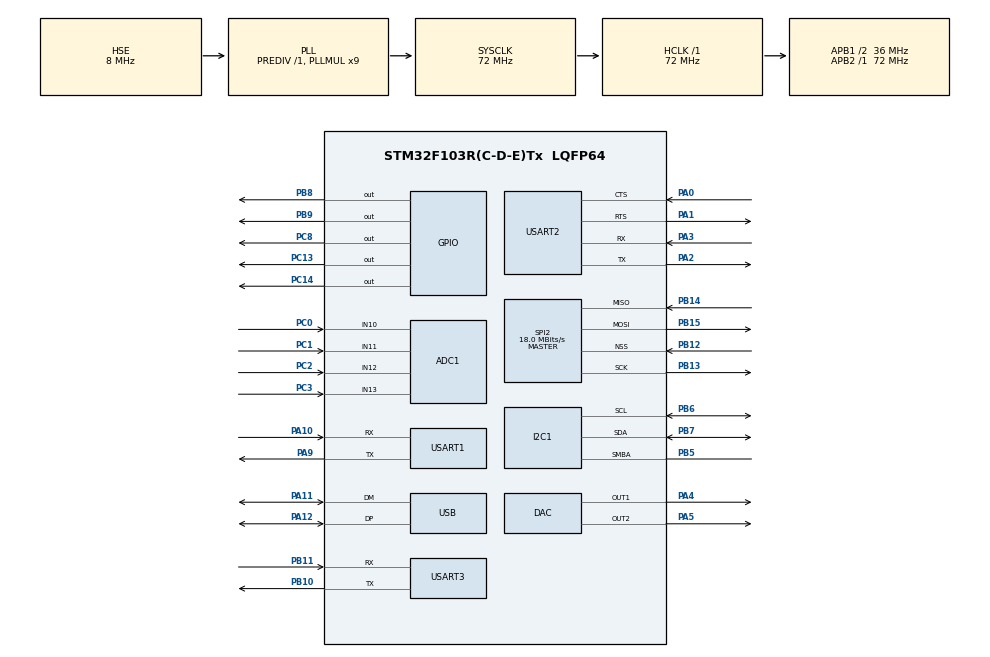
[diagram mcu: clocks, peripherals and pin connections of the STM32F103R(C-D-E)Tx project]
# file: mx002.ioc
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ADC1.Channel-0\#ChannelRegularConversion=ADC_CHANNEL_10
ADC1.ContinuousConvMode=DISABLE
ADC1.DataAlign=ADC_DATAALIGN_RIGHT
ADC1.DiscontinuousConvMode=DISABLE
ADC1.EnableAnalogWatchDog=false
ADC1.EnableRegularConversion=ENABLE
ADC1.ExternalTrigConv=ADC_SOFTWARE_START
ADC1.InjNumberOfConversion=0
ADC1.NbrOfConversion=1
ADC1.NbrOfConversionFlag=1
ADC1.Rank-0\#ChannelRegularConversion=1
ADC1.SamplingTime-0\#ChannelRegularConversion=ADC_SAMPLETIME_1CYCLE_5
ADC1.ScanConvMode=ADC_SCAN_DISABLE
ADC1.master=1
Mcu.Family=STM32F1
Mcu.Name=STM32F103R(C-D-E)Tx
Mcu.Package=LQFP64
NVIC.PriorityGroup=NVIC_PRIORITYGROUP_4
PA0-WKUP.Mode=CTS_RTS
PA0-WKUP.Signal=USART2_CTS
PA1.Mode=CTS_RTS
PA1.Signal=USART2_RTS
PA10.Mode=Asynchronous
PA10.Signal=USART1_RX
PA11.Mode=Device
PA11.Signal=USB_DM
PA12.Mode=Device
PA12.Signal=USB_DP
PA13.Mode=JTAG_5_pins
PA13.Signal=SYS_JTMS-SWDIO
PA14.Mode=JTAG_5_pins
PA14.Signal=SYS_JTCK-SWCLK
PA15.Mode=JTAG_5_pins
PA15.Signal=SYS_JTDI
PA2.Mode=Asynchronous
PA2.Signal=USART2_TX
PA3.Mode=Asynchronous
PA3.Signal=USART2_RX
PA4.Signal=COMP_DAC1_group
PA5.Signal=COMP_DAC2_group
PA9.Mode=Asynchronous
PA9.Signal=USART1_TX
PB10.Mode=Asynchronous
PB10.Signal=USART3_TX
PB11.Mode=Asynchronous
PB11.Signal=USART3_RX
PB12.Mode=NSS_Signal_Hard_Input
PB12.Signal=SPI2_NSS
PB13.Mode=Full_Duplex_Master
PB13.Signal=SPI2_SCK
PB14.Mode=Full_Duplex_Master
PB14.Signal=SPI2_MISO
PB15.Mode=Full_Duplex_Master
PB15.Signal=SPI2_MOSI
PB3.Mode=JTAG_5_pins
PB3.Signal=SYS_JTDO-TRACESWO
PB4.Mode=JTAG_5_pins
PB4.Signal=SYS_NJTRST
PB5.Mode=SMBus-Alert-mode
PB5.Signal=I2C1_SMBA
PB6.Mode=SMBus-Alert-mode
PB6.Signal=I2C1_SCL
PB7.Mode=SMBus-Alert-mode
PB7.Signal=I2C1_SDA
PB8.Signal=GPIO_Output
PB9.Signal=GPIO_Output
PC0.Signal=ADCx_IN10
PC1.Signal=ADCx_IN11
PC13-TAMPER-RTC.Signal=GPIO_Output
PC14-OSC32_IN.Signal=GPIO_Output
PC2.Signal=ADCx_IN12
PC3.Signal=ADCx_IN13
PC8.Signal=GPIO_Output
PD0-OSC_IN.Mode=HSE-External-Oscillator
PD0-OSC_IN.Signal=RCC_OSC_IN
PD1-OSC_OUT.Mode=HSE-External-Oscillator
PD1-OSC_OUT.Signal=RCC_OSC_OUT
ProjectManager.HeapSize=0x200
ProjectManager.StackSize=0x400
ProjectManager.TargetToolchain=SW4STM32
RCC.ADCPresc=RCC_ADCPCLK2_DIV6
RCC.AHBFreq_Value=72000000
RCC.APB1CLKDivider=RCC_HCLK_DIV2
RCC.APB1Freq_Value=36000000
RCC.APB1TimFreq_Value=72000000
RCC.APB2Freq_Value=72000000
RCC.APB2TimFreq_Value=72000000
RCC.HCLKFreq_Value=72000000
RCC.PLLMUL=RCC_PLL_MUL9
RCC.SYSCLKFreq_VALUE=72000000
RCC.SYSCLKSource=RCC_SYSCLKSOURCE_PLLCLK
RCC.USBFreq_Value=48000000
RCC.USBPrescaler=RCC_USBCLKSOURCE_PLL_DIV1_5
SH.ADCx_IN10.0=ADC1_IN10,IN10
SH.ADCx_IN11.0=ADC1_IN11,IN11
SH.ADCx_IN12.0=ADC1_IN12,IN12
SH.ADCx_IN13.0=ADC1_IN13,IN13
SH.COMP_DAC1_group.0=DAC_OUT1,DAC_OUT1
SH.COMP_DAC2_group.0=DAC_OUT2,DAC_OUT2
SPI2.CalculateBaudRate=18.0 MBits/s
SPI2.Direction=SPI_DIRECTION_2LINES
SPI2.Mode=SPI_MODE_MASTER
SPI2.VirtualNSS=VM_NSSHARD
SPI2.VirtualType=VM_MASTER
USART1.VirtualMode=VM_ASYNC
USART2.VirtualMode=VM_ASYNC
USART3.VirtualMode=VM_ASYNC
board=mx002

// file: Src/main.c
/**
  ******************************************************************************
  * File Name          : main.c
  * Description        : Main program body
  ******************************************************************************
  ** This notice applies to any and all portions of this file
  * that are not between comment pairs USER CODE BEGIN and
  * USER CODE END. Other portions of this file, whether
  * inserted by the user or by software development tools
  * are owned by their respective copyright owners.
  *
  * COPYRIGHT(c) 2017 STMicroelectronics
  *
  * Redistribution and use in source and binary forms, with or without modification,
  * are permitted provided that the following conditions are met:
  *   1. Redistributions of source code must retain the above copyright notice,
  *      this list of conditions and the following disclaimer.
  *   2. Redistributions in binary form must reproduce the above copyright notice,
  *      this list of conditions and the following disclaimer in the documentation
  *      and/or other materials provided with the distribution.
  *   3. Neither the name of STMicroelectronics nor the names of its contributors
  *      may be used to endorse or promote products derived from this software
  *      without specific prior written permission.
  *
  * THIS SOFTWARE IS PROVIDED BY THE COPYRIGHT HOLDERS AND CONTRIBUTORS "AS IS"
  * AND ANY EXPRESS OR IMPLIED WARRANTIES, INCLUDING, BUT NOT LIMITED TO, THE
  * IMPLIED WARRANTIES OF MERCHANTABILITY AND FITNESS FOR A PARTICULAR PURPOSE ARE
  * DISCLAIMED. IN NO EVENT SHALL THE COPYRIGHT HOLDER OR CONTRIBUTORS BE LIABLE
  * FOR ANY DIRECT, INDIRECT, INCIDENTAL, SPECIAL, EXEMPLARY, OR CONSEQUENTIAL
  * DAMAGES (INCLUDING, BUT NOT LIMITED TO, PROCUREMENT OF SUBSTITUTE GOODS OR
  * SERVICES; LOSS OF USE, DATA, OR PROFITS; OR BUSINESS INTERRUPTION) HOWEVER
  * CAUSED AND ON ANY THEORY OF LIABILITY, WHETHER IN CONTRACT, STRICT LIABILITY,
  * OR TORT (INCLUDING NEGLIGENCE OR OTHERWISE) ARISING IN ANY WAY OUT OF THE USE
  * OF THIS SOFTWARE, EVEN IF ADVISED OF THE POSSIBILITY OF SUCH DAMAGE.
  *
  ******************************************************************************
  */
#include "main.h"
#include "stm32f1xx_hal.h"

ADC_HandleTypeDef hadc1;

DAC_HandleTypeDef hdac;

SPI_HandleTypeDef hspi2;

UART_HandleTypeDef huart1;
UART_HandleTypeDef huart2;
UART_HandleTypeDef huart3;

PCD_HandleTypeDef hpcd_USB_FS;

/* USER CODE BEGIN PV */
/* Private variables ---------------------------------------------------------*/

/* USER CODE END PV */

void SystemClock_Config(void);
static void MX_GPIO_Init(void);
static void MX_USB_PCD_Init(void);
static void MX_DAC_Init(void);
static void MX_ADC1_Init(void);
static void MX_I2C1_Init(void);
static void MX_USART2_UART_Init(void);
static void MX_USART3_UART_Init(void);
static void MX_SPI2_Init(void);
static void MX_USART1_UART_Init(void);

/* USER CODE BEGIN PFP */
/* Private function prototypes -----------------------------------------------*/

/* USER CODE END PFP */

int main(void)
{

  /* MCU Configuration----------------------------------------------------------*/

  /* Reset of all peripherals, Initializes the Flash interface and the Systick. */
  HAL_Init();

  /* Configure the system clock */
  SystemClock_Config();

  /* Initialize all configured peripherals */
  MX_GPIO_Init();
  MX_USB_PCD_Init();
  MX_DAC_Init();
  MX_ADC1_Init();
  MX_I2C1_Init();
  MX_USART2_UART_Init();
  MX_USART3_UART_Init();
  MX_SPI2_Init();
  MX_USART1_UART_Init();

  /* Infinite loop */
  /* USER CODE BEGIN WHILE */

  //*************************************************************************** TESTING DAC
  HAL_DAC_SetValue(&hdac, DAC_CHANNEL_1, DAC_ALIGN_12B_R, 2048);
  HAL_DAC_SetValue(&hdac, DAC_CHANNEL_2, DAC_ALIGN_12B_R, 1024);

  HAL_DAC_Start(&hdac, DAC_CHANNEL_1);
  HAL_DAC_Start(&hdac, DAC_CHANNEL_2);

  while (1)
  {
  /* USER CODE END WHILE */

  /* USER CODE BEGIN 3 */

	  //*************************************************************************** TESTING LED
	  HAL_GPIO_TogglePin(GPIOC, GPIO_PIN_8);	// toggle LED

	  //*************************************************************************** TESTING RELAYS
	  HAL_GPIO_TogglePin(GPIOB, GPIO_PIN_9);  // toggle relay
// 	    HAL_Delay(100);
//	    HAL_GPIO_TogglePin(GPIOC, GPIO_PIN_9);  // toggle relay

	    /* Insert delay 100 ms */
 	    HAL_Delay(300);

  }
  /* USER CODE END 3 */

}

/** System Clock Configuration
*/
void SystemClock_Config(void)
{

  RCC_OscInitTypeDef RCC_OscInitStruct;
  RCC_ClkInitTypeDef RCC_ClkInitStruct;
  RCC_PeriphCLKInitTypeDef PeriphClkInit;

    /**Initializes the CPU, AHB and APB busses clocks
    */
  RCC_OscInitStruct.OscillatorType = RCC_OSCILLATORTYPE_HSE;
  RCC_OscInitStruct.HSEState = RCC_HSE_ON;
  RCC_OscInitStruct.HSEPredivValue = RCC_HSE_PREDIV_DIV1;
  RCC_OscInitStruct.HSIState = RCC_HSI_ON;
  RCC_OscInitStruct.PLL.PLLState = RCC_PLL_ON;
  RCC_OscInitStruct.PLL.PLLSource = RCC_PLLSOURCE_HSE;
  RCC_OscInitStruct.PLL.PLLMUL = RCC_PLL_MUL9;
  if (HAL_RCC_OscConfig(&RCC_OscInitStruct) != HAL_OK)
  {
    _Error_Handler(__FILE__, __LINE__);
  }

    /**Initializes the CPU, AHB and APB busses clocks
    */
  RCC_ClkInitStruct.ClockType = RCC_CLOCKTYPE_HCLK|RCC_CLOCKTYPE_SYSCLK
                              |RCC_CLOCKTYPE_PCLK1|RCC_CLOCKTYPE_PCLK2;
  RCC_ClkInitStruct.SYSCLKSource = RCC_SYSCLKSOURCE_PLLCLK;
  RCC_ClkInitStruct.AHBCLKDivider = RCC_SYSCLK_DIV1;
  RCC_ClkInitStruct.APB1CLKDivider = RCC_HCLK_DIV2;
  RCC_ClkInitStruct.APB2CLKDivider = RCC_HCLK_DIV1;

  if (HAL_RCC_ClockConfig(&RCC_ClkInitStruct, FLASH_LATENCY_2) != HAL_OK)
  {
    _Error_Handler(__FILE__, __LINE__);
  }

  PeriphClkInit.PeriphClockSelection = RCC_PERIPHCLK_ADC|RCC_PERIPHCLK_USB;
  PeriphClkInit.AdcClockSelection = RCC_ADCPCLK2_DIV6;
  PeriphClkInit.UsbClockSelection = RCC_USBCLKSOURCE_PLL_DIV1_5;
  if (HAL_RCCEx_PeriphCLKConfig(&PeriphClkInit) != HAL_OK)
  {
    _Error_Handler(__FILE__, __LINE__);
  }

    /**Configure the Systick interrupt time
    */
  HAL_SYSTICK_Config(HAL_RCC_GetHCLKFreq()/1000);

    /**Configure the Systick
    */
  HAL_SYSTICK_CLKSourceConfig(SYSTICK_CLKSOURCE_HCLK);

  /* SysTick_IRQn interrupt configuration */
  HAL_NVIC_SetPriority(SysTick_IRQn, 0, 0);
}

/* ADC1 init function */
static void MX_ADC1_Init(void)
{

  ADC_ChannelConfTypeDef sConfig;

    /**Common config
    */
  hadc1.Instance = ADC1;
  hadc1.Init.ScanConvMode = ADC_SCAN_DISABLE;
  hadc1.Init.ContinuousConvMode = DISABLE;
  hadc1.Init.DiscontinuousConvMode = DISABLE;
  hadc1.Init.ExternalTrigConv = ADC_SOFTWARE_START;
  hadc1.Init.DataAlign = ADC_DATAALIGN_RIGHT;
  hadc1.Init.NbrOfConversion = 1;
  if (HAL_ADC_Init(&hadc1) != HAL_OK)
  {
    _Error_Handler(__FILE__, __LINE__);
  }

    /**Configure Regular Channel
    */
  sConfig.Channel = ADC_CHANNEL_10;
  sConfig.Rank = 1;
  sConfig.SamplingTime = ADC_SAMPLETIME_1CYCLE_5;
  if (HAL_ADC_ConfigChannel(&hadc1, &sConfig) != HAL_OK)
  {
    _Error_Handler(__FILE__, __LINE__);
  }

}

/* DAC init function */
static void MX_DAC_Init(void)
{

  DAC_ChannelConfTypeDef sConfig;

    /**DAC Initialization
    */
  hdac.Instance = DAC;
  if (HAL_DAC_Init(&hdac) != HAL_OK)
  {
    _Error_Handler(__FILE__, __LINE__);
  }

    /**DAC channel OUT1 config
    */
  sConfig.DAC_Trigger = DAC_TRIGGER_NONE;
  sConfig.DAC_OutputBuffer = DAC_OUTPUTBUFFER_ENABLE;
  if (HAL_DAC_ConfigChannel(&hdac, &sConfig, DAC_CHANNEL_1) != HAL_OK)
  {
    _Error_Handler(__FILE__, __LINE__);
  }

    /**DAC channel OUT2 config
    */
  if (HAL_DAC_ConfigChannel(&hdac, &sConfig, DAC_CHANNEL_2) != HAL_OK)
  {
    _Error_Handler(__FILE__, __LINE__);
  }

}

/* I2C1 init function */
static void MX_I2C1_Init(void)
{

}

/* SPI2 init function */
static void MX_SPI2_Init(void)
{

  hspi2.Instance = SPI2;
  hspi2.Init.Mode = SPI_MODE_MASTER;
  hspi2.Init.Direction = SPI_DIRECTION_2LINES;
  hspi2.Init.DataSize = SPI_DATASIZE_8BIT;
  hspi2.Init.CLKPolarity = SPI_POLARITY_LOW;
  hspi2.Init.CLKPhase = SPI_PHASE_1EDGE;
  hspi2.Init.NSS = SPI_NSS_HARD_INPUT;
  hspi2.Init.BaudRatePrescaler = SPI_BAUDRATEPRESCALER_2;
  hspi2.Init.FirstBit = SPI_FIRSTBIT_MSB;
  hspi2.Init.TIMode = SPI_TIMODE_DISABLE;
  hspi2.Init.CRCCalculation = SPI_CRCCALCULATION_DISABLE;
  hspi2.Init.CRCPolynomial = 10;
  if (HAL_SPI_Init(&hspi2) != HAL_OK)
  {
    _Error_Handler(__FILE__, __LINE__);
  }

}

/* USART1 init function */
static void MX_USART1_UART_Init(void)
{

  huart1.Instance = USART1;
  huart1.Init.BaudRate = 115200;
  huart1.Init.WordLength = UART_WORDLENGTH_8B;
  huart1.Init.StopBits = UART_STOPBITS_1;
  huart1.Init.Parity = UART_PARITY_NONE;
  huart1.Init.Mode = UART_MODE_TX_RX;
  huart1.Init.HwFlowCtl = UART_HWCONTROL_NONE;
  huart1.Init.OverSampling = UART_OVERSAMPLING_16;
  if (HAL_UART_Init(&huart1) != HAL_OK)
  {
    _Error_Handler(__FILE__, __LINE__);
  }

}

/* USART2 init function */
static void MX_USART2_UART_Init(void)
{

  huart2.Instance = USART2;
  huart2.Init.BaudRate = 115200;
  huart2.Init.WordLength = UART_WORDLENGTH_8B;
  huart2.Init.StopBits = UART_STOPBITS_1;
  huart2.Init.Parity = UART_PARITY_NONE;
  huart2.Init.Mode = UART_MODE_TX_RX;
  huart2.Init.HwFlowCtl = UART_HWCONTROL_RTS_CTS;
  huart2.Init.OverSampling = UART_OVERSAMPLING_16;
  if (HAL_UART_Init(&huart2) != HAL_OK)
  {
    _Error_Handler(__FILE__, __LINE__);
  }

}

/* USART3 init function */
static void MX_USART3_UART_Init(void)
{

  huart3.Instance = USART3;
  huart3.Init.BaudRate = 115200;
  huart3.Init.WordLength = UART_WORDLENGTH_8B;
  huart3.Init.StopBits = UART_STOPBITS_1;
  huart3.Init.Parity = UART_PARITY_NONE;
  huart3.Init.Mode = UART_MODE_TX_RX;
  huart3.Init.HwFlowCtl = UART_HWCONTROL_NONE;
  huart3.Init.OverSampling = UART_OVERSAMPLING_16;
  if (HAL_UART_Init(&huart3) != HAL_OK)
  {
    _Error_Handler(__FILE__, __LINE__);
  }

}

/* USB init function */
static void MX_USB_PCD_Init(void)
{

  hpcd_USB_FS.Instance = USB;
  hpcd_USB_FS.Init.dev_endpoints = 8;
  hpcd_USB_FS.Init.speed = PCD_SPEED_FULL;
  hpcd_USB_FS.Init.ep0_mps = DEP0CTL_MPS_8;
  hpcd_USB_FS.Init.low_power_enable = DISABLE;
  hpcd_USB_FS.Init.lpm_enable = DISABLE;
  hpcd_USB_FS.Init.battery_charging_enable = DISABLE;
  if (HAL_PCD_Init(&hpcd_USB_FS) != HAL_OK)
  {
    _Error_Handler(__FILE__, __LINE__);
  }

}

/** Configure pins as
        * Analog
        * Input
        * Output
        * EVENT_OUT
        * EXTI
     PB5   ------> I2C1_SMBA
     PB6   ------> I2C1_SCL
     PB7   ------> I2C1_SDA
*/
static void MX_GPIO_Init(void)
{

  GPIO_InitTypeDef GPIO_InitStruct;

  /* GPIO Ports Clock Enable */
  __HAL_RCC_GPIOC_CLK_ENABLE();
  __HAL_RCC_GPIOD_CLK_ENABLE();
  __HAL_RCC_GPIOA_CLK_ENABLE();
  __HAL_RCC_GPIOB_CLK_ENABLE();

  /*Configure GPIO pin Output Level */
  HAL_GPIO_WritePin(GPIOC, GPIO_PIN_13|GPIO_PIN_14|GPIO_PIN_8, GPIO_PIN_RESET);

  /*Configure GPIO pin Output Level */
  HAL_GPIO_WritePin(GPIOB, GPIO_PIN_8|GPIO_PIN_9, GPIO_PIN_RESET);

  /*Configure GPIO pins : PC13 PC14 PC8 */
  GPIO_InitStruct.Pin = GPIO_PIN_13|GPIO_PIN_14|GPIO_PIN_8;
  GPIO_InitStruct.Mode = GPIO_MODE_OUTPUT_PP;
  GPIO_InitStruct.Speed = GPIO_SPEED_FREQ_LOW;
  HAL_GPIO_Init(GPIOC, &GPIO_InitStruct);

  /*Configure GPIO pins : PB5 PB6 PB7 */
  GPIO_InitStruct.Pin = GPIO_PIN_5|GPIO_PIN_6|GPIO_PIN_7;
  GPIO_InitStruct.Mode = GPIO_MODE_AF_OD;
  GPIO_InitStruct.Speed = GPIO_SPEED_FREQ_HIGH;
  HAL_GPIO_Init(GPIOB, &GPIO_InitStruct);

  /*Configure GPIO pins : PB8 PB9 */
  GPIO_InitStruct.Pin = GPIO_PIN_8|GPIO_PIN_9;
  GPIO_InitStruct.Mode = GPIO_MODE_OUTPUT_PP;
  GPIO_InitStruct.Speed = GPIO_SPEED_FREQ_LOW;
  HAL_GPIO_Init(GPIOB, &GPIO_InitStruct);

}

void _Error_Handler(char * file, int line)
{
  while(1)
  {
  }
}

/************************ (C) COPYRIGHT STMicroelectronics *****END OF FILE****/
